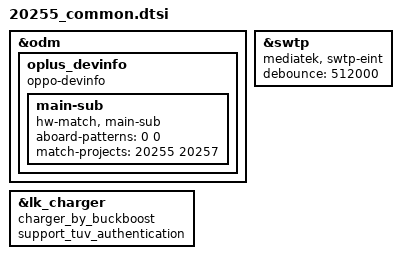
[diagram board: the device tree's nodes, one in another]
&odm  {
	oplus_devinfo:oplus_devinfo {
	compatible = "oppo-devinfo";
	main-sub {
		compatible = "hw-match, main-sub";
		aboard-patterns = <0 0>;
		/*main board*/
		match-projects = <20255 20257>;
	};
	};
};
//#ifdef OPLUS_FEATURE_CHG_BASIC
&lk_charger{
	charger_by_buckboost;
	support_tuv_authentication;
};
//#endif

//#ifdef OPLUS_FEATURE_SWTP
&swtp {
	compatible = "mediatek, swtp-eint";
	debounce = <512000>;
};
//#endif
